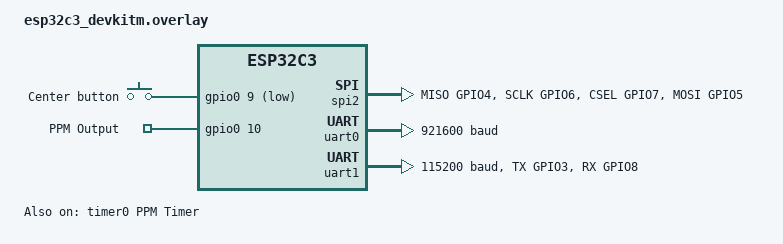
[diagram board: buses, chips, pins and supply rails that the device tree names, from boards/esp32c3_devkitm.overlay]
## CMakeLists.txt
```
cmake_minimum_required(VERSION 3.20.0)
set(BOARD esp32c3_devkitm)

find_package(Zephyr REQUIRED HINTS $ENV{ZEPHYR_BASE})
project(HeadTracker_ESP32)

zephyr_compile_options(-Wno-missing-braces)

FILE(GLOB app_sources src/*.c src/*/*.c)
target_sources(app PRIVATE ${app_sources})
```

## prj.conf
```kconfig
# Sensor
# CONFIG_I2C=y
# CONFIG_SENSOR=y
# CONFIG_MPU9250=y
# CONFIG_MPU9250_TRIGGER_NONE=y
# CONFIG_MPU9250_MAGN_EN=y
CONFIG_SPI=y
# CONFIG_SENSOR=y
# CONFIG_ICM42688=y
# CONFIG_ICM42688_TRIGGER_NONE=y

# Sys
CONFIG_POLL=y

# Math
CONFIG_NEWLIB_LIBC=y
CONFIG_NEWLIB_LIBC_NANO=y
CONFIG_NEWLIB_LIBC_FLOAT_PRINTF=y


# Flash
CONFIG_FLASH=y
CONFIG_FLASH_PAGE_LAYOUT=y
CONFIG_SOC_FLASH_ESP32=y
CONFIG_MPU_ALLOW_FLASH_WRITE=y

# Counter
CONFIG_COUNTER=y
CONFIG_COUNTER_TMR_ESP32=y

# Bluetooth
CONFIG_BT=y
CONFIG_BT_DEBUG_LOG=y
CONFIG_BT_SMP=y
CONFIG_BT_PERIPHERAL=y
CONFIG_BT_DEVICE_NAME="HeadTracker_ESP32"
CONFIG_BT_CTLR_PHY_2M=y
CONFIG_BT_CTLR_PHY_CODED=y
CONFIG_BT_L2CAP_TX_MTU=65
CONFIG_BT_GAP_AUTO_UPDATE_CONN_PARAMS=n

# UART / USB
CONFIG_SERIAL=y
# CONFIG_DMA=y
# CONFIG_DMA_ESP32=y
CONFIG_UART_ASYNC_API=y
CONFIG_UART_INTERRUPT_DRIVEN=y
CONFIG_UART_USE_RUNTIME_CONFIGURE=y

# Debug
CONFIG_LOG=y
CONFIG_LOG_MODE_IMMEDIATE=y

# # Thread Information
# CONFIG_THREAD_MONITOR=y
CONFIG_DEBUG_THREAD_INFO=y

# Show Thread Information, Use a logging method below (RTT preferred)
CONFIG_THREAD_ANALYZER=y
CONFIG_THREAD_ANALYZER_USE_LOG=y
CONFIG_THREAD_ANALYZER_AUTO=y
CONFIG_THREAD_ANALYZER_AUTO_STACK_SIZE=2048
CONFIG_THREAD_ANALYZER_AUTO_INTERVAL=10

# Disable not used
```

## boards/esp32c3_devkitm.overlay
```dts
/ {
    gpio_keys {
        compatible = "gpio-keys";
        center_button: center_button {
            label = "Center button";
            gpios = <&gpio0 9 (GPIO_PULL_UP | GPIO_ACTIVE_LOW)>;
        };
        ppm_pin: ppm {
            label = "PPM Output";
            gpios = <&gpio0 10 (GPIO_PULL_DOWN | GPIO_ACTIVE_HIGH)>;
        };
    };
};

&pinctrl {
    spim2_imu: spim2_imu {
        group1 {
            pinmux = <SPIM2_MISO_GPIO4>,
                     <SPIM2_SCLK_GPIO6>,
                     <SPIM2_CSEL_GPIO7>;
        };
        group2 {
            pinmux = <SPIM2_MOSI_GPIO5>;
            output-low;
        };
    };
    uart1_sbus: uart1_sbus
    {
        group1 {
            pinmux = <UART1_TX_GPIO3>,
                     <UART1_RX_GPIO8>;
        };
    };
};
// &i2c0 {
    //     mpu9250: mpu9250@68 {
        //         compatible = "invensense,mpu9250";
        //         reg = <0x68>;
        //         status = "okay";
        //         gyro-sr-div = <(1000/140-1)>;   //(1000/rate-1)
        //         gyro-dlpf = <41>;
        //         gyro-fs = <2000>;
        //         accel-fs = <2>;
        //         accel-dlpf = "10.2";
    //     };
// };

&spi2 {
    #address-cells = <1>;
    #size-cells = <0>;
    status = "okay";
    pinctrl-0 = <&spim2_imu>;
    pinctrl-names = "default";
    // icm42688: icm42688@0 {
        //     compatible = "invensense,icm42688";
        //     spi-max-frequency = <3000000>;
        //     reg = <0>;
        //     label = "icm42688";
        //     accel-fs = <2>;
        //     gyro-fs = <2000>;
        //     accel-hz = <1000>;
        //     gyro-hz = <1000>;
    // };
};

&timer0 {
    status = "ok";
    label = "PPM Timer";
    prescaler = <80>;
    group = <0>;
    index = <0>;
};
/* Flash Layout
 *    Bootloader    0x00000 - 0x10000 (Size 0x10000 64Kb)
 *    Code0         0x10000 - 0x206000 (Size 0x1F6000 2008Kb)
 *    Code1         0x206000 - 0x3FC000 (Size 0x1F6000 2008Kb)
 *    NVM Data      0x3FC000 - 0x400000 (Size 0x4000 16kb)
 */

// &flash0 {
    //     partitions {
        //         compatible = "fixed-partitions";
        //         #address-cells = <1>;
        //         #size-cells = <1>;

        //         boot_partition: partition@0 {
            //             label = "mcuboot";
            //             reg = <0x00000000 0x10000>;
            //             read-only;
        //         };
        //         code0_partition: partition@10000 {
            //             label = "code0";
            //             reg = <0x10000 0x1F6000>;
        //         };
        //         code1_partition: partition@206000 {
            //             label = "code1";
            //             reg = <0x206000 0x1F6000>;
        //         };
        //         datapt_partition: partition@3FC000 {
            //             label = "datapt";
            //             reg = <0x3FC000 0x4000>;
        //         };
    //     };
// };

&dma {
    status = "okay";
};

&uart0 {
    current-speed = <921600>;
};

&uart1 {
    status = "okay";
    current-speed = <115200>;
    pinctrl-0 = <&uart1_sbus>;
    pinctrl-names = "default";
    // parity = "odd";
    // stop-bits = "2";
    // data-bits = <8>;
    // dmas = <&dma 3>, <&dma 5>;
    // dma-names = "tx", "rx";
};
```

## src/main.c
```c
#include <zephyr/kernel.h>
#include <zephyr/device.h>
#include <zephyr/drivers/sensor.h>
#include <zephyr/logging/log.h>

#include "application.h"


int main(void)
{
	printk("Hello World! %s\n", CONFIG_BOARD);

	start();

	return 0;
}
```

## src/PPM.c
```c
#include "PPM.h"

#include <zephyr/device.h>
#include <zephyr/drivers/gpio.h>
#include <zephyr/drivers/counter.h>
#include <zephyr/logging/log.h>
#include <stdio.h>

#include "defines.h"
#include "imu.h"
#include "trackersettings.h"

//------------------------------------------------------------------------------
// Defines
#define DT_TIMER DT_NODELABEL(timer0)
#define DT_PPM_PIN DT_NODELABEL(ppm_pin)
#define ALARM_CHANNEL_ID 0
#define DELAY 100000

//------------------------------------------------------------------------------
// Macro Modules

LOG_MODULE_REGISTER(ppmLog, LOG_LEVEL_DBG);

//------------------------------------------------------------------------------
// Private Values
struct counter_alarm_cfg alarm_cfg;

// Used to read data at once, read with isr disabled
static uint16_t ch_values[16];
static int ch_count;

static uint16_t framesync = PPM_MIN_FRAMESYNC; // Minimum Frame Sync Pulse
static int32_t framelength;                    // Ideal frame length
static uint16_t sync;                          // Sync Pulse Length

// Local data - Only build with interrupts disabled
static uint32_t chsteps[35] = {PPM_MIN_FRAMESYNC, PPM_MIN_SYNC};

// ISR Values - Values from chsteps are copied here on step 0.
// prevent an update from happening mid stream.
static uint32_t isrchsteps[35] = {PPM_MIN_FRAMESYNC, PPM_MIN_SYNC};
static uint16_t chstepcnt = 1;
static uint16_t curstep = 0;
volatile bool buildingdata = false;

/**
 * @brief PPM timer callback function.
 */
static void ppm_counter_interrupt_fn(const struct device *counter_dev,
                                     uint8_t chan_id, uint32_t ticks,
                                     void *user_data)
{
    static const struct gpio_dt_spec ppm_dev = GPIO_DT_SPEC_GET(DT_PPM_PIN, gpios);
    struct counter_alarm_cfg *config = user_data;
    uint32_t now_ticks;
    static uint32_t ticks_offset = 0;
    int err;

    err = counter_get_value(counter_dev, &now_ticks);
    if (err)
    {
        LOG_ERR("Failed to read counter value (err %d)", err);
        return;
    }

    // Reset, don't get stuck in the wrong signal level
    if (curstep == 0)
    {
        // set the first output signal level
        if (isPPMininvert())
            gpio_pin_set_dt(&ppm_dev, 1);
        else
            gpio_pin_set_dt(&ppm_dev, 0);
    }
    // Not last frame
    else if (curstep < chstepcnt - 1)
    {
        gpio_pin_toggle_dt(&ppm_dev);
    }

    // Setup next capture event value
    // int ticks_over_flag = 0; // test
    config->ticks = ticks_offset + isrchsteps[curstep];
    if (now_ticks > config->ticks)
    {
        // ticks_over_flag = 1; // test
        // Reset offset, usually happened at the beginning
        ticks_offset = (curstep > 0) ? (now_ticks - isrchsteps[curstep - 1]) : now_ticks;
        config->ticks = ticks_offset + isrchsteps[curstep];
    }

    curstep++;
    // Loop
    if (curstep > chstepcnt)
    {
        if (!buildingdata)
            memcpy(isrchsteps, chsteps, sizeof(isrchsteps[0]) * 35);
        curstep = 0;
        ticks_offset = config->ticks;
    }

    /* Set a new alarm with a double length duration */
    err = counter_set_channel_alarm(counter_dev, ALARM_CHANNEL_ID,
                                    user_data);
    if (err != 0)
    {
        LOG_ERR("Alarm could not be set");
    }

    // printk("[%s]", now_str());
    // printk("step: %d\n", curstep);
    // printk("ticks: %d\n", now_ticks);
    // printk("over: %d\n", ticks_over_flag);
    // printk("next ticks: %d\n", config->ticks);
    // counter_get_value(counter_dev, &now_ticks);
    // printk("now ticks: %d\n", now_ticks);
    // uint32_t buff = now_ticks;
    // counter_get_value(counter_dev, &now_ticks);
    // printk("elipsed: %d\n", now_ticks - buff);
}

int PPMinit(void)
{
    ch_count = getPPMchcnt();
    sync = getPPMsync();
    framelength = getPPMframe();

    int ret;

    const struct gpio_dt_spec ppm_dev = GPIO_DT_SPEC_GET(DT_PPM_PIN, gpios);
    if (!gpio_is_ready_dt(&ppm_dev))
    {
        LOG_ERR("Error: button device %s is not ready\r\n", ppm_dev.port->name);
        return 0;
    }

    ret = gpio_pin_configure_dt(&ppm_dev, GPIO_OUTPUT);
    if (ret != 0)
    {
        LOG_ERR("Error %d: failed to configure %s pin %d\r\n",
                ret, ppm_dev.port->name, ppm_dev.pin);
        return 0;
    }

    const struct device *const counter_dev = DEVICE_DT_GET(DT_TIMER);
    if (!device_is_ready(counter_dev))
    {
        LOG_ERR("timer not ready.\r\n");
        return 0;
    }

    // Set all channels to center
    for (int i = 0; i < 16; i++)
        ch_values[i] = 1500;

    // Init counter data
    buildChannels();
    // printPPMdata(); // test
    memcpy(isrchsteps, chsteps, sizeof(isrchsteps[0]) * 35);

    // Start ppm counter
    counter_start(counter_dev);

    alarm_cfg.flags = 1;
    alarm_cfg.ticks = counter_us_to_ticks(counter_dev, DELAY);
    alarm_cfg.callback = ppm_counter_interrupt_fn;
    alarm_cfg.user_data = &alarm_cfg;

    // LOG_DBG("alarm freq:%d\n", counter_get_frequency(counter_dev)); // test
    ret = counter_set_channel_alarm(counter_dev, ALARM_CHANNEL_ID,
                                    &alarm_cfg);
    if (-EINVAL == ret)
    {
        LOG_ERR("Alarm settings invalid\r\n");
    }
    else if (-ENOTSUP == ret)
    {
        LOG_ERR("Alarm setting request not supported\r\n");
    }
    else if (ret != 0)
    {
        LOG_ERR("Error\r\n");
    }

    return 0;
}

/**
 * @brief Build timer data for isr to change IO according to Channel data(pwm values).
 */
void buildChannels(void)
{
    buildingdata = true; // Prevent a read happing while this is building

    // Set user defined channel count, frame len, sync pulse
    ch_count = getPPMchcnt();
    sync = getPPMsync();
    framelength = getPPMframe();

    int ch = 0;
    int i;
    uint32_t curtime = framesync;
    chsteps[0] = curtime;
    for (i = 1; i <= ch_count * 2 + 1; i += 2)
    {
        curtime += sync;
        chsteps[i] = curtime;
        curtime += (ch_values[ch++] - sync);
        chsteps[i + 1] = curtime;
    }
    // Add Final Sync
    curtime += sync;
    chsteps[i++] = curtime;
    chstepcnt = i;
    // Now we know how long the train is. Try to make the entire frame == framelength
    // If possible it will add this to the frame sync pulse

    if (framelength >= curtime)
        chsteps[i] = framelength; // Store at end of sequence
    else
        chsteps[i] = 0; // Not possible, no time left
    buildingdata = false;
}

void PpmOut_setChannel(int chan, uint16_t val)
{
    if (chan >= 0 && chan <= ch_count && val >= MIN_PWM &&
        val <= MAX_PWM)
    {
        ch_values[chan] = val;
    }
}

int PpmOut_getChnCount() { return ch_count; }

// test function
void printPPMdata(void)
{
    for (uint8_t i = 0; i < sizeof(chsteps) / sizeof(chsteps[0]); i++)
    {
        printf("%d ", chsteps[i]);
    }
    printf("\r\n");
}
```

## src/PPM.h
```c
#ifndef PPM_H
#define PPM_H

#include <zephyr/kernel.h>

int PPMinit(void);
void buildChannels(void);
void PpmOut_setChannel(int chan, uint16_t val);
int PpmOut_getChnCount();

void printPPMdata(void);    //test

#endif
```

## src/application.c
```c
#include "application.h"
#include "defines.h"
#include "imu.h"
#include "PPM.h"
#include "io.h"
#include "bt.h"
#include "uart.h"


void start(void)
{
    io_Init();
    PPMinit();
    uart_init();
    imu_Init();
    bt_init();
}

K_THREAD_DEFINE(imu_Thread_id, 2048, imu_Thread, NULL, NULL, NULL, IMU_THREAD_PRIO,
                0, 100);
K_THREAD_DEFINE(calculate_Thread_id, 2048, calculate_Thread, NULL, NULL, NULL,
                CALCULATE_THREAD_PRIO, 0, 100);
K_THREAD_DEFINE(io_Thread_id, 512, io_Thread, NULL, NULL, NULL, IO_THREAD_PRIO, 0, 0);
K_THREAD_DEFINE(bt_Thread_id, 1024, bt_Thread, NULL, NULL, NULL, BT_THREAD_PRIO, 0, 0);
K_THREAD_DEFINE(uart_Thread_id, 1024, uart_Thread, NULL, NULL, NULL, UARTTX_THREAD_PRIO, 0, 200);
```

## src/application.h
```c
#ifndef APPLICATION_H
#define APPLICATION_H

#include <zephyr/kernel.h>

void start(void);

#endif
```

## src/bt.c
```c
#include "bt.h"

#include <zephyr/kernel.h>
#include <stdio.h>

#include <zephyr/bluetooth/bluetooth.h>
#include <zephyr/bluetooth/conn.h>
#include <zephyr/bluetooth/uuid.h>
#include <zephyr/bluetooth/gatt.h>
#include <zephyr/logging/log.h>

#include "io.h"
#include "imu.h"
#include "trackersettings.h"

//------------------------------------------------------------------------------
// Defines
#define DEVICE_NAME CONFIG_BT_DEVICE_NAME
#define DEVICE_NAME_LEN (sizeof(DEVICE_NAME) - 1)
#define BT_HEADTRACKER_UUID_VALUE 0x4EF0
#define BT_PWM_UUID_VALUE 0x4EF1

//------------------------------------------------------------------------------
// Macro Modules
LOG_MODULE_REGISTER(BtLog, LOG_LEVEL_DBG);

//------------------------------------------------------------------------------
// Private Values
static uint8_t curmode = 0;                         // current bt mode
static uint8_t bt_pwm_value[BT_CHANNELS * 2] = {0}; // pwm data to be sent via Bluetooth

static struct k_poll_signal btThreadRunSignal = K_POLL_SIGNAL_INITIALIZER(btThreadRunSignal);
struct k_poll_event btRunEvents[1] = {
    K_POLL_EVENT_INITIALIZER(K_POLL_TYPE_SIGNAL, K_POLL_MODE_NOTIFY_ONLY, &btThreadRunSignal),
};

/* BLE connection */
struct bt_conn *conn;

// Service UUID
static struct bt_uuid_16 bt_service_uuid = BT_UUID_INIT_16(
    BT_HEADTRACKER_UUID_VALUE);

// UUID's
struct bt_uuid_16 bt_pwm_uuid = BT_UUID_INIT_16(BT_PWM_UUID_VALUE);

// Bluetooth advertisement data
static const struct bt_data ad[] = {
    BT_DATA_BYTES(BT_DATA_FLAGS, (BT_LE_AD_GENERAL | BT_LE_AD_NO_BREDR)),
    BT_DATA(BT_DATA_NAME_COMPLETE, DEVICE_NAME, DEVICE_NAME_LEN),
    BT_DATA_BYTES(BT_DATA_UUID16_SOME, BT_UUID_16_ENCODE(BT_HEADTRACKER_UUID_VALUE))};

//--------------------Function Defines--------------------
void printBtData(void);

static void mpu_ccc_cfg_changed(const struct bt_gatt_attr *attr, uint16_t value)
{
    ARG_UNUSED(attr);
    LOG_INF("Notification %s", (value == BT_GATT_CCC_NOTIFY) ? "enabled" : "disabled");
}

BT_GATT_SERVICE_DEFINE(
    bt_srv,
    // ATTRIBUTE 0
    BT_GATT_PRIMARY_SERVICE(&bt_service_uuid),

    // Data output Characteristic  ATTRIBUTE 1,2
    BT_GATT_CHARACTERISTIC(&bt_pwm_uuid.uuid,
                           BT_GATT_CHRC_NOTIFY,
                           BT_GATT_PERM_READ, NULL, NULL, bt_pwm_value),
    BT_GATT_CCC(mpu_ccc_cfg_changed, BT_GATT_PERM_READ | BT_GATT_PERM_WRITE),

);

static void connected(struct bt_conn *connected, uint8_t err)
{
    if (err)
    {
        LOG_ERR("Connection failed (err %u)", err);
    }
    else
    {
        LOG_INF("Connected");
        if (!conn)
        {
            conn = bt_conn_ref(connected);
        }

        struct bt_conn_info info;
        bt_conn_get_info(connected, &info);

        LOG_INF("BT Connection Params Int:%d Lat:%d Timeout:%d", info.le.interval, info.le.latency,
                info.le.timeout);
    }
}

static void disconnected(struct bt_conn *disconn, uint8_t reason)
{
    if (conn)
    {
        bt_conn_unref(conn);
        conn = NULL;
    }

    LOG_INF("Disconnected (reason %u)", reason);

    /* Start advertising */
    int err = bt_le_adv_start(BT_LE_ADV_CONN, ad, ARRAY_SIZE(ad), NULL, 0);
    if (err)
    {
        LOG_ERR("Advertising failed to start (err %d)", err);
        return;
    }

    LOG_INF("Configuration mode: waiting connections...");
}

BT_CONN_CB_DEFINE(conn_callbacks) = {
    .connected = connected,
    .disconnected = disconnected,
};

void BTHeadStart()
{
    /* Start advertising */
    int err = bt_le_adv_start(BT_LE_ADV_CONN, ad, ARRAY_SIZE(ad), NULL, 0);
    if (err)
    {
        LOG_ERR("Advertising failed to start (err %d)", err);
        return;
    }

    LOG_INF("Configuration mode: waiting connections...");
}

void BTHeadStop()
{
    // Stop Advertising
    int err = bt_le_adv_stop();
    if (err)
    {
        LOG_ERR("BLE Unable to Stop advertising");
    }
    else
    {
        LOG_INF("BLE Stopped Advertising");
    }
}

void BTHeadExecute()
{
    if (conn)
    {
        // Send Trainer Data
        // int64_t uselepsed = micros64();
        bt_gatt_notify(NULL, &bt_srv.attrs[2], bt_pwm_value, sizeof(bt_pwm_value));
        printBtData();
        // uselepsed = micros64() - uselepsed;
        // LOG_DBG("Notify cost: %lld", uselepsed);
    }
}

void bt_ready(int error)
{
    BTHeadStart();
    k_poll_signal_raise(&btThreadRunSignal, 1);
}

void bt_init()
{
    int err = bt_enable(bt_ready);
    if (err)
    {
        LOG_ERR("bt_enable failed (err %d)", err);
        return;
    }
    for (uint8_t i = 0; i < sizeof(bt_pwm_value); i += 2)
    {
        bt_pwm_value[i] = (uint8_t)(1500 & 0xff);
        bt_pwm_value[i + 1] = (uint8_t)(1500 >> 8);
    }
}

void bt_Thread()
{
    int64_t usduration = 0;
    while (1)
    {
        k_poll(btRunEvents, 1, K_FOREVER);

        usduration = micros64();

        BTHeadExecute();

        // Adjust sleep for a more accurate period
        usduration = micros64() - usduration;
        if (BT_PERIOD - usduration <
            BT_PERIOD * 0.7)
        { // Took a long time. Will crash if sleep is too short
            k_usleep(BT_PERIOD);
        }
        else
        {
            k_usleep(BT_PERIOD - usduration);
        }
    }
}

void buildBtChannels(uint16_t *channelData, uint8_t channels)
{
    for (uint8_t i = 0; i < channels; i++)
    {
        bt_pwm_value[i * 2] = channelData[i] >> 8;
        bt_pwm_value[i * 2 + 1] = channelData[i] & 0xff;
    }
}

void printBtData(void)
{
    uint16_t u16_val;
    printf("[%s]", now_str());
    for (uint8_t i = 0; i < BT_CHANNELS; i++)
    {
        u16_val = (bt_pwm_value[i * 2] << 8) | bt_pwm_value[i * 2 + 1];
        printf("%d  ", u16_val);
    }
    printf("\r\n");
}
```

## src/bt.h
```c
#ifndef BT_H
#define BT_H

#include <zephyr/kernel.h>
#include "defines.h"


void bt_Thread();
void bt_init();

/**
 * @brief Build channel data for Bluetooth to sent
 * @param channelData pointer to the source channel data to be converted
 * @param channels the number of channels to be converted
 */
void buildBtChannels(uint16_t *channelData, uint8_t channels);



#endif
```

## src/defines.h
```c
#ifndef DEFINES_H
#define DEFINES_H

// Math
#ifndef M_PI
#define M_PI (3.14159265358979323846)
#endif
#define M_G 9.806650

#define SAMPLE_RATE (int)(1000000 / IMU_PERIOD) // IMU sample rate, replace this with actual sample rate(Hz)

// Thread Periods
#define IO_PERIOD 5              // (ms) IO Period (button reading)
#define BT_PERIOD 7500           // (us) Bluetooth update rate
// #define SERIAL_PERIOD 30       // (ms) Serial processing
// #define DATA_PERIOD 2          // Multiplier of Serial Period (Live Data Transmission Speed)
#define IMU_PERIOD 5000             // (us) Sensor Reads
#define CALCULATE_PERIOD IMU_PERIOD // (us) Channel Calculations
#define UART_PERIOD 4000       // (us) Update rate of UART
// #define PWM_FREQUENCY 50       // (ms) PWM Period
// #define PAUSE_BEFORE_FLASH 60  // (ms) Time to pause all threads before Flash writing

// Thread Priority Definitions
#define PRIORITY_LOW 12
#define PRIORITY_MED 9
#define PRIORITY_HIGH 6
#define PRIORITY_RT 3

// Thread Periods, Negative values mean cannot be pre-empted
#define IO_THREAD_PRIO PRIORITY_LOW
// #define SERIAL_THREAD_PRIO PRIORITY_LOW
// #define DATA_THREAD_PRIO PRIORITY_LOW
#define BT_THREAD_PRIO -15
#define IMU_THREAD_PRIO PRIORITY_MED
#define CALCULATE_THREAD_PRIO PRIORITY_HIGH
// #define UARTRX_THREAD_PRIO PRIORITY_LOW - 2
#define UARTTX_THREAD_PRIO PRIORITY_HIGH

#define millis64() k_cyc_to_ms_floor64(k_cycle_get_64())
#define micros64() k_cyc_to_us_floor64(k_cycle_get_64())

#endif
```

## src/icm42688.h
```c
#ifndef ICM42688_H
#define ICM42688_H

#include <zephyr/kernel.h>

#define USE_ICM42688

/**
 * @brief Initiate icm42688 config
 * @param dev pointer to device
 * @return 0 if success, others if failed
 */
int icm42688_Init(const struct device *dev);

/**
 * @brief read accelerator and gyro spi data
 * @param dev pointer to device
 * @param reading pointer to data to be stored
 * @param len length of data to read
 * @return 0 if success, others if failed
 */
int icm42688_AccGyr_fetch(const struct device *dev, uint8_t *reading, uint8_t len);

/**
 * @brief get accelerator data in g from spi data
 * @param rawAccel pointer to spi data
 * @param racc_array pointer to accelerator data in g to be stored
 */
void icm42688_acc_get(uint8_t *rawAccel, float *racc_array);

/**
 * @brief get gyro data in g from spi data
 * @param rawGyro pointer to spi data
 * @param rgyr_array pointer to gyro data in g to be stored
 */
void icm42688_gyr_get(uint8_t *rawGyro, float *rgyr_array);

#endif
```

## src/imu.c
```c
#include "imu.h"

#include <zephyr/kernel.h>
#include <zephyr/device.h>
#include <zephyr/drivers/spi.h>
#include <zephyr/drivers/sensor.h>
#include <zephyr/logging/log.h>
#include <stdio.h>
#include <string.h>

#include "defines.h"
#include "io.h"
#include "ppm.h"
#include "bt.h"
#include "Fusion/Fusion.h"
#include "trackersettings.h"
#include "icm42688/icm42688.h"

//------------------------------------------------------------------------------
// Defines
#define DT_IMU DT_NODELABEL(spi2)
#define IMU_HOLD 1
#define IMU_RECOVER 0
//------------------------------------------------------------------------------
// Macro Modules
LOG_MODULE_REGISTER(imuLog, LOG_LEVEL_DBG);
K_MUTEX_DEFINE(imu_mutex);

//------------------------------------------------------------------------------
// Private Functions Declarations
float normalize(const float value, const float start, const float end);

//------------------------------------------------------------------------------
// Private Values

static const struct device *imu_Dev = DEVICE_DT_GET(DT_IMU);
static FusionVector racc = {0}; // Raw values in g
static FusionVector rgyr = {0}; // Raw values in d/s
static FusionVector rmag = {0}; // Raw values in guss
static FusionVector acc = {0};  // in g
static FusionVector gyr = {0};  // in d/s
static FusionVector mag = {0};  // in guss
static float tilt = 0, roll = 0, pan = 0;
static float rolloffset = 0, panoffset = 0, tiltoffset = 0; // Center offset, used when pressed center button

static uint16_t channel_data[MAX_CHANNELS] = {PPM_CENTER}; // Range 0-2500

static ImuStatus imuStatus = {
    .hold = 0,
    .reserved = 0,
    .eularHold = {0, 0, 0},
};
// static float accxoff = 0, accyoff = 0, acczoff = 0;
// static float gyrxoff = 0, gyryoff = 0, gyrzoff = 0;

/**
 * @brief IMU thread runs when the signal is set.
 */
static struct k_poll_signal imuThreadRunSignal = K_POLL_SIGNAL_INITIALIZER(imuThreadRunSignal);
struct k_poll_event imuRunEvents[1] = {
    K_POLL_EVENT_INITIALIZER(K_POLL_TYPE_SIGNAL, K_POLL_MODE_NOTIFY_ONLY, &imuThreadRunSignal),
};

/**
 * @brief Calculate thread runs when the signal is set.
 */
static struct k_poll_signal calculateThreadRunSignal =
    K_POLL_SIGNAL_INITIALIZER(calculateThreadRunSignal);
struct k_poll_event calculateRunEvents[1] = {
    K_POLL_EVENT_INITIALIZER(K_POLL_TYPE_SIGNAL, K_POLL_MODE_NOTIFY_ONLY, &calculateThreadRunSignal),
};

//--------------------Function Defines--------------------

/**
 * @brief Initialises the IMU device.
 */
int imu_Init(void)
{
    if (!device_is_ready(imu_Dev))
    {
        LOG_ERR("Device %s is not ready\r\n", imu_Dev->name);
        return -ENODEV;
    }
    else
    {
        // Start reading the IMU sensors + fusion algorithm
        icm42688_Init(imu_Dev);

        k_poll_signal_raise(&imuThreadRunSignal, 1);
    }

    // Set IMU Offset. For Test
    // gyrxoff = 0.004608 - 0.001077;
    // gyryoff = -0.0253 + 0.00173;
    // gyrzoff = -0.002058 + 0.001139;

    // accxoff = 0;
    // accyoff = 0;
    // acczoff = 0;

    return 0;
}

/**
 * @brief IMU Reading Channel Thread.
 */
void imu_Thread(void)
{
    // static int64_t sleepElapse = 0;
    int64_t usImuElapse = 0;

    while (1)
    {
        // Only run when imuThreadRunSignal is raised
        k_poll(imuRunEvents, 1, K_FOREVER);

        usImuElapse = micros64(); // Timestamp record

        k_mutex_lock(&imu_mutex, K_FOREVER);
#ifdef USE_ICM42688
        // ICM42688--------------------------

        // acc data size(2*3) + gyro data size(2*3)
        uint8_t readings[12];
        // 1) Read Raw IMU Data
        if (!icm42688_AccGyr_fetch(imu_Dev, readings, sizeof(readings)))
        {
            icm42688_acc_get(&readings[0], racc.array);
            icm42688_gyr_get(&readings[6], rgyr.array);

            memcpy(acc.array, racc.array, sizeof(acc));
            memcpy(gyr.array, rgyr.array, sizeof(gyr));
        }
        else
        {
            LOG_ERR("Get IMU data failed!");
        }
        // ICM42688--------------------------
#else
        if (!sensor_sample_fetch(imu_Dev))
        {
            struct sensor_value tmp[3];
            uint8_t res = 0;

            // 1) Read Raw IMU Data
            // -- Accelerometer
            res = sensor_channel_get(imu_Dev, SENSOR_CHAN_ACCEL_XYZ, tmp);
            if (!res)
            {
                racc.axis.x = (float)sensor_value_to_double(&tmp[0]);
                racc.axis.y = (float)sensor_value_to_double(&tmp[1]);
                racc.axis.z = (float)sensor_value_to_double(&tmp[2]);

                racc.axis.x = ms2_to_g(racc.axis.x);
                racc.axis.y = ms2_to_g(racc.axis.y);
                racc.axis.z = ms2_to_g(racc.axis.z);

                memcpy(acc.array, racc.array, sizeof(acc));

                // acc.axis.x = racc.axis.x - accxoff;
                // acc.axis.y = racc.axis.y - accyoff;
                // acc.axis.z = racc.axis.z - acczoff;
            }
            else
                LOG_ERR("Get accelerometer data failed!");

            // -- Gyrometer
            res = sensor_channel_get(imu_Dev, SENSOR_CHAN_GYRO_XYZ, tmp);
            if (!res)
            {
                rgyr.axis.x = (float)sensor_value_to_double(&tmp[0]);
                rgyr.axis.y = (float)sensor_value_to_double(&tmp[1]);
                rgyr.axis.z = (float)sensor_value_to_double(&tmp[2]);

                rgyr.axis.x = rad_to_degrees(rgyr.axis.x);
                rgyr.axis.y = rad_to_degrees(rgyr.axis.y);
                rgyr.axis.z = rad_to_degrees(rgyr.axis.z);

                memcpy(gyr.array, rgyr.array, sizeof(gyr));

                // gyr.axis.x = rgyr.axis.x - gyrxoff;
                // gyr.axis.y = rgyr.axis.y - gyryoff;
                // gyr.axis.z = rgyr.axis.z - gyrzoff;
            }
            else
                LOG_ERR("Get gyrometer data failed!");

            // -- Magnetometer
            if (isUsingMagn())
            {
                res = sensor_channel_get(imu_Dev, SENSOR_CHAN_MAGN_XYZ, tmp);
                if (!res)
                {
                    rmag.axis.x = (float)sensor_value_to_double(&tmp[0]);
                    rmag.axis.y = (float)sensor_value_to_double(&tmp[1]);
                    rmag.axis.z = (float)sensor_value_to_double(&tmp[2]);
                }
                else
                    LOG_ERR("Get gyrometer data failed!");
            }
            else
            {
                mag.axis.x = 0;
                mag.axis.y = 0;
                mag.axis.z = 0;
            }

            // 3) Apply Rotation
        }
        else
        {
            LOG_ERR("Get IMU data failed!");
        }
#endif

        k_mutex_unlock(&imu_mutex);

        // printf("%f,%f,%f\r\n", rgyr.axis.x, rgyr.axis.y, rgyr.axis.z); // test

        // printf("\r\n\r\n[%s]\r\n", now_str());                               // test
        // printf("rgyr: %f,%f,%f\r\n", rgyr.axis.x, rgyr.axis.y, rgyr.axis.z); // test
        // printf("racc: %f,%f,%f\r\n", racc.axis.x, racc.axis.y, racc.axis.z); // test
        // printf("gyr0: %f,%f,%f\r\n", gyr.axis.x, gyr.axis.y, gyr.axis.z);    // test
        // printf("acc0: %f,%f,%f\r\n", acc.axis.x, acc.axis.y, acc.axis.z);    // test

        // Start doing the other calculations
        k_poll_signal_raise(&calculateThreadRunSignal, 1);

        // Adjust sleep for a more accurate period
        usImuElapse = micros64() - usImuElapse;
        // Took a long time. Will crash if sleep is too short
        // printk("%lld\n",usImuElapse);
        if (IMU_PERIOD - usImuElapse < IMU_PERIOD * 0.5)
        {
            k_usleep(IMU_PERIOD);
        }
        else
        {
            // k_usleep precision is actually 1ms, it will round up the time to sleep
            // minus 1ms to fix the that
            k_usleep(IMU_PERIOD - usImuElapse - 1000);
        }
    }
}

/**
 * @brief Calculations and Main Channel Thread.
 */
void calculate_Thread(void)
{
    // Define calibration (replace with actual calibration data if available)
    const FusionMatrix gyroscopeMisalignment = {1.0f, 0.0f, 0.0f, 0.0f, 1.0f, 0.0f, 0.0f, 0.0f, 1.0f};
    const FusionVector gyroscopeSensitivity = {1.0f, 1.0f, 1.0f};
    const FusionMatrix accelerometerMisalignment = {1.0f, 0.0f, 0.0f, 0.0f, 1.0f, 0.0f, 0.0f, 0.0f, 1.0f};
    const FusionVector accelerometerSensitivity = {1.0f, 1.0f, 1.0f};
    const FusionMatrix softIronMatrix = {1.0f, 0.0f, 0.0f, 0.0f, 1.0f, 0.0f, 0.0f, 0.0f, 1.0f};
    const FusionVector hardIronOffset = {0.0f, 0.0f, 0.0f};

    FusionVector gyroscopeOffset;
    FusionVector accelerometerOffset;

    for (uint8_t i = 0; i < 3; i++)
    {
        accelerometerOffset.array[i] = getAccOffset(i);
        gyroscopeOffset.array[i] = getGyrOffset(i);
    }

    // printf("accelerometerOffset: %f %f %f\r\n", accelerometerOffset.array[0], accelerometerOffset.array[1], accelerometerOffset.array[2]);
    // printf("gyroscopeOffset: %f %f %f\r\n", gyroscopeOffset.array[0], gyroscopeOffset.array[1], gyroscopeOffset.array[2]);

    // Initialise algorithms
    FusionOffset offset;
    FusionAhrs ahrs;

    FusionOffsetInitialise(&offset, SAMPLE_RATE);
    FusionAhrsInitialise(&ahrs);

    // Set AHRS algorithm settings
    const FusionAhrsSettings settings = {
        .convention = FusionConventionNwu,
        .gain = 0.5f,
        .accelerationRejection = 10.0f,
        .magneticRejection = 20.0f,
        .rejectionTimeout = 5 * SAMPLE_RATE, /* 5 seconds */
    };
    FusionAhrsSetSettings(&ahrs, &settings);

    // This loop should repeat each time new gyroscope data is available
    while (true)
    {
        k_poll(calculateRunEvents, 1, K_FOREVER);

        // Acquire latest sensor data
        const int64_t timestamp = micros64();            // replace this with actual gyroscope timestamp
        FusionVector gyroscope = {0.0f, 0.0f, 0.0f};     // replace this with actual gyroscope data in degrees/s
        FusionVector accelerometer = {0.0f, 0.0f, 1.0f}; // replace this with actual accelerometer data in g
        FusionVector magnetometer = {1.0f, 0.0f, 0.0f};  // replace this with actual magnetometer data in arbitrary units

        // Use a mutex so sensor data can't be updated part way
        k_mutex_lock(&imu_mutex, K_FOREVER);

        memcpy(accelerometer.array, acc.array, sizeof(accelerometer));
        memcpy(gyroscope.array, gyr.array, sizeof(gyroscope));

        if (isUsingMagn())
        {
            memcpy(magnetometer.array, mag.array, sizeof(magnetometer));
            magnetometer = FusionCalibrationMagnetic(magnetometer, softIronMatrix, hardIronOffset);
        }
        k_mutex_unlock(&imu_mutex);

        // Apply calibration
        gyroscope = FusionCalibrationInertial(gyroscope, gyroscopeMisalignment, gyroscopeSensitivity, gyroscopeOffset);
        accelerometer = FusionCalibrationInertial(accelerometer, accelerometerMisalignment, accelerometerSensitivity, accelerometerOffset);

        // Update gyroscope offset correction algorithm
        gyroscope = FusionOffsetUpdate(&offset, gyroscope);

        // Calculate delta time (in seconds) to account for gyroscope sample clock error
        static int64_t previousTimestamp = 0;
        const float deltaTime = (float)(timestamp - previousTimestamp) / (float)USEC_PER_SEC;
        previousTimestamp = timestamp;

        // Update gyroscope AHRS algorithm
        if (isUsingMagn())
            FusionAhrsUpdate(&ahrs, gyroscope, accelerometer, magnetometer, deltaTime);
        else
            FusionAhrsUpdateNoMagnetometer(&ahrs, gyroscope, accelerometer, deltaTime);

        // Convert pitch/roll/yaw to roll/tilt/pan
        const FusionEuler euler = FusionQuaternionToEuler(FusionAhrsGetQuaternion(&ahrs));
        roll = euler.angle.roll;
        tilt = euler.angle.pitch;
        pan = euler.angle.yaw;

        // printf("%f,%f,%f\r\n", euler.angle.roll, euler.angle.pitch, euler.angle.yaw); // test

        // printf("Roll %0.1f, Pitch %0.1f, Yaw %0.1f\r\n"
        //        "Ax %f, Ay %f, Az %f\r\n"
        //        "Gx %f, Gy %f, Gz %f\r\n"
        //        "Mx %f, My %f, Mz %f\r\n",
        //        euler.angle.roll, euler.angle.pitch, euler.angle.yaw,
        //        accelerometer.axis.x, accelerometer.axis.y, accelerometer.axis.z,
        //        gyroscope.axis.x, gyroscope.axis.y, gyroscope.axis.z,
        //        magnetometer.axis.x, magnetometer.axis.y, magnetometer.axis.z);

        // Zero button was pressed, adjust all values to zero
        if (isSingleClick())
        {
            rolloffset = roll;
            tiltoffset = tilt;
            panoffset = pan;
            imuStatus.hold = 0; // recover output
        }
        else if (isLongStart())
        {
            switch (imuStatus.hold)
            {
            case IMU_RECOVER:
                imuStatus.hold = IMU_HOLD;
                imuStatus.eularHold.axis.roll = roll;
                imuStatus.eularHold.axis.tilt = tilt;
                imuStatus.eularHold.axis.pan = pan;
                break;
            case IMU_HOLD:
                imuStatus.hold = IMU_RECOVER;
                // Adjust offset to make the output from current position
                rolloffset = roll - (imuStatus.eularHold.axis.roll - rolloffset);
                tiltoffset = tilt - (imuStatus.eularHold.axis.tilt - tiltoffset);
                panoffset = pan - (imuStatus.eularHold.axis.pan - panoffset);
                break;
            default:
                break;
            }
        }

        // Hold the output eular
        if (imuStatus.hold == IMU_HOLD)
        {
            roll = imuStatus.eularHold.axis.roll;
            tilt = imuStatus.eularHold.axis.tilt;
            pan = imuStatus.eularHold.axis.pan;
        }

        // Tilt output
        float tiltout =
            (tilt - tiltoffset) * getTiltGain() * (isTiltReversed() ? -1.0 : 1.0);
        uint16_t tiltout_ui = tiltout + getTiltCnt();                  // Apply Center Offset
        tiltout_ui = MAX(MIN(tiltout_ui, getTiltMax()), getTiltMin()); // Limit Output

        // Roll output
        float rollout =
            (roll - rolloffset) * getRollGain() * (isRollReversed() ? -1.0 : 1.0);
        uint16_t rollout_ui = rollout + getRollCnt();                  // Apply Center Offset
        rollout_ui = MAX(MIN(rollout_ui, getRollMax()), getRollMin()); // Limit Output

        // Pan output, Normalize to +/- 180 Degrees
        float panout = normalize((pan - panoffset), -180, 180) * getPanGain() *
                       (isPanReversed() ? -1.0 : 1.0);
        uint16_t panout_ui = panout + getPanCnt();                 // Apply Center Offset
        panout_ui = MAX(MIN(panout_ui, getPanMax()), getPanMin()); // Limit Output

        // // Reset on tilt
        // static bool doresetontilt = false;
        // if (trkset.getRstOnTlt())
        // {
        //     static bool tiltpeak = false;
        //     static float resettime = 0.0f;
        //     enum
        //     {
        //         HITNONE,
        //         HITMIN,
        //         HITMAX,
        //     };
        //     static int minmax = HITNONE;
        //     if (rollout_ui == trkset.getRll_Max())
        //     {
        //         if (tiltpeak == false && minmax == HITNONE)
        //         {
        //             tiltpeak = true;
        //             minmax = HITMAX;
        //         }
        //         else if (minmax == HITMIN)
        //         {
        //             minmax = HITNONE;
        //             tiltpeak = false;
        //             doresetontilt = true;
        //         }
        //     }
        //     else if (rollout_ui == trkset.getRll_Min())
        //     {
        //         if (tiltpeak == false && minmax == HITNONE)
        //         {
        //             tiltpeak = true;
        //             minmax = HITMIN;
        //         }
        //         else if (minmax == HITMAX)
        //         {
        //             minmax = HITNONE;
        //             tiltpeak = false;
        //             doresetontilt = true;
        //         }
        //     }

        //     // If hit a max/min wait an amount of time and reset it
        //     if (tiltpeak == true)
        //     {
        //         resettime += (float)CALCULATE_PERIOD / 1000000.0;
        //         if (resettime > TrackerSettings::RESET_ON_TILT_TIME)
        //         {
        //             tiltpeak = false;
        //             minmax = HITNONE;
        //             resettime = 0;
        //         }
        //     }
        // }

        // // Do the actual reset after a delay
        // static float timetoreset = 0;
        // if (doresetontilt)
        // {
        //     if (timetoreset > TrackerSettings::RESET_ON_TILT_AFTER)
        //     {
        //         doresetontilt = false;
        //         timetoreset = 0;
        //         pressButton();
        //     }
        //     timetoreset += (float)CALCULATE_PERIOD / 1000000.0;
        // }

        // Build PPM channel data
        // Reset all channels to center
        for (uint8_t i = 0; i < (sizeof(channel_data) / sizeof(channel_data[0])); i++)
            channel_data[i] = PPM_CENTER;

        // Set Tilt/Roll/Pan Channel Values
        uint8_t tltch = getTiltChl();
        uint8_t rllch = getRollChl();
        uint8_t panch = getPanChl();
        if (tltch > 0)
            channel_data[tltch - 1] = isTiltEn() == true ? tiltout_ui : getTiltCnt();
        if (rllch > 0)
            channel_data[rllch - 1] = isRollEn() == true ? rollout_ui : getRollCnt();
        if (panch > 0)
            channel_data[panch - 1] = isPanEn() == true ? panout_ui : getPanCnt();

        // 10) Set the PPM Outputs
        for (uint8_t i = 0; i < PpmOut_getChnCount(); i++)
        {
            uint16_t ppmout = channel_data[i];
            if (ppmout == 0)
                ppmout = PPM_CENTER;
            PpmOut_setChannel(i, ppmout);
        }
        buildChannels();

        // 11) Set the SBUS Outputs
        sbusBuildChannels(channel_data);

        // 12) Set the BT Outputs
        buildBtChannels(channel_data, BT_CHANNELS);

        // int elipsed = micros64() - timestamp;
        // printf("[%d]:\r\n", elipsed);

        // printf("%0.1f,%0.1f,%0.1f\r\n", tilt - tiltoffset,
        //        roll - rolloffset,
        //        pan - panoffset); // test
        // printf("%f,%f,%f\r\n", racc.axis.x, racc.axis.y, racc.axis.z); // test
        // printf("%f,%f,%f\r\n", gyr.axis.x, gyr.axis.y, gyr.axis.z); // test
        // printf("%f,%f,%f\r\n", gyroscope.axis.x, gyroscope.axis.y, gyroscope.axis.z); // test
        // printf("%f,%f,%f\r\n", accelerometer.axis.x, accelerometer.axis.y, accelerometer.axis.z); // test

        // printPPMdata(); // test

        k_poll_signal_reset(&calculateThreadRunSignal);
        // printf("[%s] cal1\r\n", now_str()); // test

        // // Adjust sleep for a more accurate period
        // usImuElapse = micros64() - usImuElapse;
        // // Took a long time. Will crash if sleep is too short
        // if (CALCULATE_PERIOD - usImuElapse < CALCULATE_PERIOD * 0.7)
        // {
        //     k_usleep(CALCULATE_PERIOD);
        // }
        // else
        // {
        //     k_usleep(CALCULATE_PERIOD - usImuElapse);
        // }
    }
}

// FROM https://stackoverflow.com/questions/1628386/normalise-orientation-between-0-and-360
// Normalizes any number to an arbitrary range
// by assuming the range wraps around when going below min or above max
float normalize(const float value, const float start, const float end)
{
    const float width = end - start;         //
    const float offsetValue = value - start; // value relative to 0

    return (offsetValue - (floor(offsetValue / width) * width)) + start;
    // + start to reset back to start of original range
}

void getChannelData(uint16_t *buffer)
{
    memcpy(buffer, channel_data, sizeof(channel_data));
}

const char *now_str(void)
{
    static char buf[24]; /* ...HH:MM:SS.MMM,UUU */
    uint64_t now = micros64();
    uint16_t us = now % USEC_PER_MSEC;
    uint16_t ms;
    uint8_t s;
    uint8_t min;
    uint32_t h;

    now /= USEC_PER_MSEC;
    ms = now % MSEC_PER_SEC;
    now /= MSEC_PER_SEC;
    s = now % 60U;
    now /= 60U;
    min = now % 60U;
    now /= 60U;
    h = now;

    snprintf(buf, sizeof(buf), "%u:%02u:%02u.%03u,%03u",
             h, min, s, ms, us);
    return buf;
}
```

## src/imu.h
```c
#ifndef IMU_H
#define IMU_H

//------------------------------------------------------------------------------
// Includes

#include <zephyr/kernel.h>
#include <math.h> // M_PI, sqrtf, atan2f, asinf

#include "defines.h"

//------------------------------------------------------------------------------
// Type
typedef union
{
    float array[3];
    struct
    {
        float roll;
        float tilt;
        float pan;
    } axis;
} EularVactor;

typedef struct
{
    uint8_t hold : 1; // hold current output position
    uint8_t reserved : 7;
    EularVactor eularHold;  //output eular when holding
} ImuStatus;

//------------------------------------------------------------------------------
// Definitions

/**
 * @brief Read Channel data(pwm values).
 * @param buffer destiny pointer, must be no smaller then sizeof(channel_data).
 */
void getChannelData(uint16_t *buffer);

int imu_Init(void);
void imu_Thread(void);
void calculate_Thread(void);

const char *now_str(void);

#endif
```

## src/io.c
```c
#include "io.h"

#include <zephyr/device.h>
#include <zephyr/drivers/gpio.h>
#include <zephyr/logging/log.h>
#include <stdio.h>

#include "defines.h"
#include "multi_button/multi_button.h"

//------------------------------------------------------------------------------
// Defines
#define DT_CENTER_BUTTON DT_NODELABEL(center_button)

//------------------------------------------------------------------------------
// Macro Modules

LOG_MODULE_REGISTER(ioLog, LOG_LEVEL_DBG);
K_SEM_DEFINE(btn1_single_click_sem, 0, 1);
K_SEM_DEFINE(btn1_long_start_sem, 0, 1);

//------------------------------------------------------------------------------
// Private Values
static const struct gpio_dt_spec cnt_button = GPIO_DT_SPEC_GET(DT_CENTER_BUTTON, gpios);
static const uint8_t btn1_id = 0;
struct Button btn1;

//--------------------Function Defines--------------------

uint8_t read_button_GPIO(uint8_t button_id)
{
    // you can share the GPIO read function with multiple Buttons
    switch (button_id)
    {
    case btn1_id:
        return gpio_pin_get_dt(&cnt_button);
    default:
        return 0;
    }
}

/**
 * @brief Initialises the IO device.
 */
int io_Init(void)
{
    int ret;

    if (!gpio_is_ready_dt(&cnt_button))
    {
        LOG_ERR("Error: button device %s is not ready\r\n", cnt_button.port->name);
        return 0;
    }

    ret = gpio_pin_configure_dt(&cnt_button, GPIO_INPUT);
    if (ret != 0)
    {
        printk("Error %d: failed to configure %s pin %d\n",
               ret, cnt_button.port->name, cnt_button.pin);
        return 0;
    }

    button_init(&btn1, read_button_GPIO, 1, btn1_id);
    button_attach(&btn1, SINGLE_CLICK, BTN1_SINGLE_Click_Handler);
    button_attach(&btn1, LONG_PRESS_START, BTN1_LONG_PRESS_START_Handler);
    button_start(&btn1);
    return 0;
}

void io_Thread(void)
{
    static uint8_t btn1_event_val;
    while (true)
    {
        button_ticks(); // read button status

        k_msleep(IO_PERIOD);
    }
}

void BTN1_SINGLE_Click_Handler(void* btn)
{
    k_sem_give(&btn1_single_click_sem);
}

void BTN1_LONG_PRESS_START_Handler(void* btn)
{
    k_sem_give(&btn1_long_start_sem);
}

/**
 * @brief Did the center button single clicked?
 * @retval true: button was single clicked.
 * @retval false: button was NOT single clicked.
 */
bool isSingleClick(void)
{
    if (k_sem_take(&btn1_single_click_sem, K_NO_WAIT))
        return false;
    return true;
}

/**
 * @brief Is the center button in long start status?
 * @retval true: button is in long start status.
 * @retval false: button is NOT in long start status.
 */
bool isLongStart(void)
{
    if (k_sem_take(&btn1_long_start_sem, K_NO_WAIT))
        return false;
    return true;
}
```

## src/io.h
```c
#ifndef IO_H
#define IO_H

#include <zephyr/kernel.h>

extern struct k_sem btn1_single_click_sem;

bool isSingleClick(void);
bool isLongStart(void);

int io_Init(void);
void io_Thread(void);

void BTN1_SINGLE_Click_Handler(void* btn);
void BTN1_LONG_PRESS_START_Handler(void* btn);

#endif
```
